# AT32F403Axx register map
Vendor: Keil; Series: AT32F403A; File version: 1.0
CPU: CM4 r0p1, little endian, no MPU, FPU, 4 interrupt priority bits
Registers are 32-bit, read-write, reset 0x0 unless marked. A register's access mark holds for its fields unless they carry their own. Offsets are from the block's base; [hi:lo] are bit positions; {n}, {i} and the like mark numbered series; 'fields as' and 'values as' point back to an identical list.

## XMC — Flexible static memory controller
Base 0xA0000000
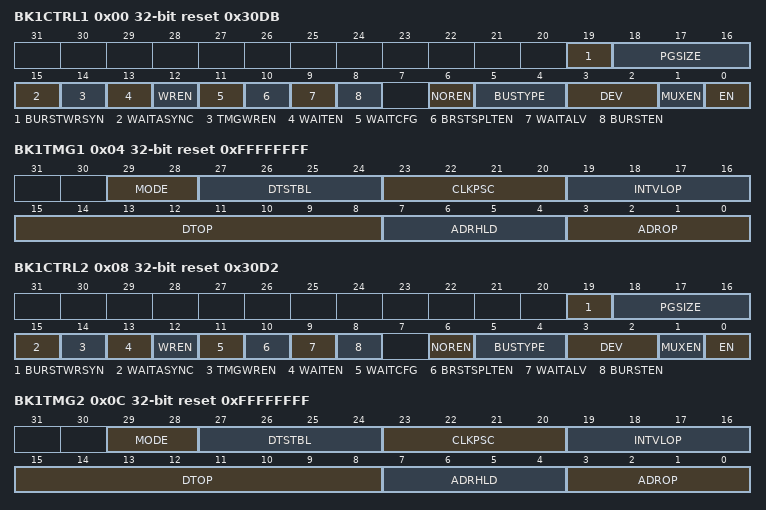
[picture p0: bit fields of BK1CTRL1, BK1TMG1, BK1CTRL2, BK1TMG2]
0x00 BK1CTRL1 reset 0x30DB — SRAM/NOR-Flash chip-select control register 1
  [19] BURSTWRSYN, [18:16] PGSIZE, [15] WAITASYNC, [14] TMGWREN, [13] WAITEN, [12] WREN, [11] WAITCFG, [10] BRSTSPLTEN, [9] WAITALV, [8] BURSTEN, [6] NOREN, [5:4] BUSTYPE, [3:2] DEV, [1] MUXEN, [0] EN
0x04 BK1TMG1 reset 0xFFFFFFFF — SRAM/NOR-Flash chip-select timing register 1
  [29:28] MODE, [27:24] DTSTBL, [23:20] CLKPSC, [19:16] INTVLOP, [15:8] DTOP, [7:4] ADRHLD, [3:0] ADROP
0x08 BK1CTRL2 reset 0x30D2 — SRAM/NOR-Flash chip-select control register 2
  fields as BK1CTRL1
0x0C BK1TMG2 reset 0xFFFFFFFF — SRAM/NOR-Flash chip-select timing register 2
  fields as BK1TMG1
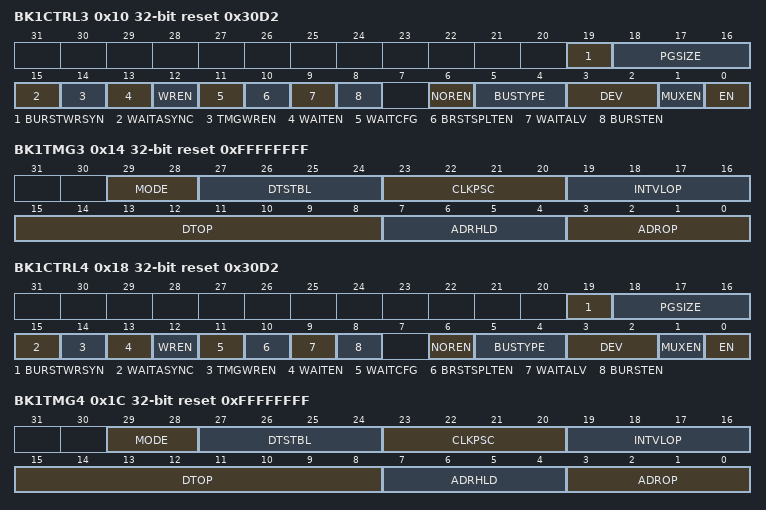
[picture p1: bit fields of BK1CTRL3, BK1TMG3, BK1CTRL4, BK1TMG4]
0x10 BK1CTRL3 reset 0x30D2 — SRAM/NOR-Flash chip-select control register 3
  fields as BK1CTRL1
0x14 BK1TMG3 reset 0xFFFFFFFF — SRAM/NOR-Flash chip-select timing register 3
  fields as BK1TMG1
0x18 BK1CTRL4 reset 0x30D2 — SRAM/NOR-Flash chip-select control register 4
  fields as BK1CTRL1
0x1C BK1TMG4 reset 0xFFFFFFFF — SRAM/NOR-Flash chip-select timing register 4
  fields as BK1TMG1
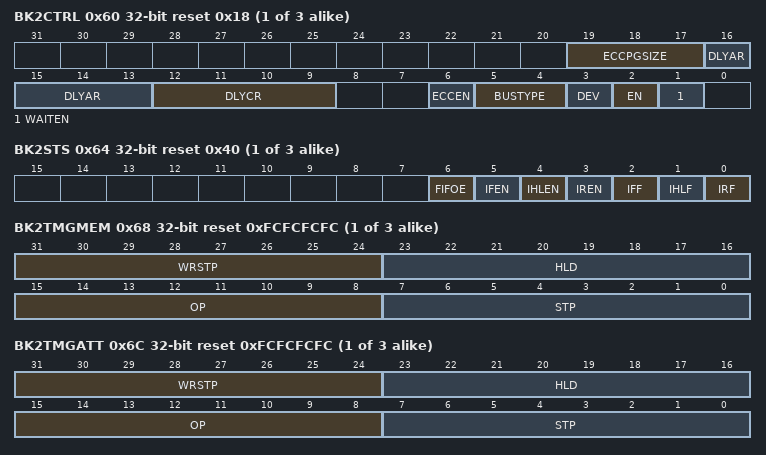
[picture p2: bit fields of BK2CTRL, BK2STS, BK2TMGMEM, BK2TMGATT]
{0x20+0x20*i} BK{i}CTRL reset 0x18 (i=2..4) — PC Card/NAND Flash control register {i}
  [19:17] ECCPGSIZE, [16:13] DLYAR, [12:9] DLYCR, [6] ECCEN, [5:4] BUSTYPE, [3] DEV, [2] EN, [1] WAITEN
{0x24+0x20*i} BK{i}STS reset 0x40 (i=2..4) — FIFO status and interrupt register {i}
  [6] FIFOE ro, [5] IFEN, [4] IHLEN, [3] IREN, [2] IFF, [1] IHLF, [0] IRF
{0x28+0x20*i} BK{i}TMGMEM reset 0xFCFCFCFC (i=2..4) — Common memory space timing register {i}
  [31:24] WRSTP, [23:16] HLD, [15:8] OP, [7:0] STP
{0x2C+0x20*i} BK{i}TMGATT reset 0xFCFCFCFC (i=2..4) — Attribute memory space timing register {i}
  [31:24] WRSTP — Attribute memory x databus HiZ time
  [23:16] HLD — Attribute memory x hold time
  [15:8] OP — Attribute memory x wait time
  [7:0] STP — Attribute memory x setup time
0x74 BK2ECC — ECC result register 2
  [31:0] ECC — ECC result
0x94 BK3ECC — ECC result register 3
  [31:0] ECC — ECC result
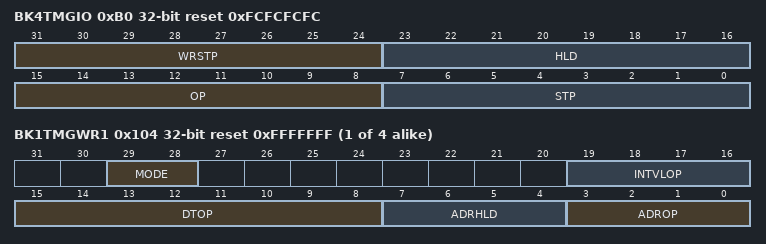
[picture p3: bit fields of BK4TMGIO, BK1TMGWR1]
0xB0 BK4TMGIO reset 0xFCFCFCFC — I/O space timing register 4
  [31:24] WRSTP, [23:16] HLD, [15:8] OP, [7:0] STP
{0xFC+8i} BK1TMGWR{i} reset 0xFFFFFFF (i=1..4) — SRAM/NOR-Flash write timing registers {i}
  [29:28] MODE, [19:16] INTVLOP, [15:8] DTOP, [7:4] ADRHLD, [3:0] ADROP

## PWR — Power control
Base 0x40007000
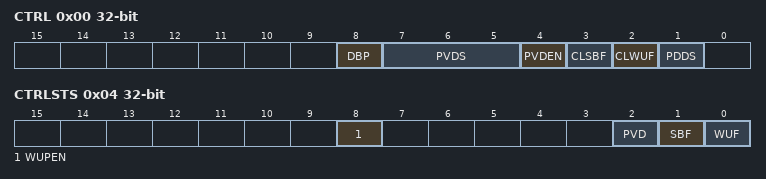
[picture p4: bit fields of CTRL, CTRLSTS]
0x00 CTRL — Power control register (PWR_CTRL)
  [8] DBP — Disable Backup Domain write protection
  [7:5] PVDS — PVD Level Selection
  [4] PVDEN — Power Voltage Detector Enable
  [3] CLSBF — Clear STANDBY Flag
  [2] CLWUF — Clear Wake-up Flag
  [1] PDDS — Power Down Deep Sleep
0x04 CTRLSTS — Power control register (PWR_CTRLST)
  [8] WUPEN — Enable WKUP pin
  [2] PVD ro — PVD Output
  [1] SBF ro — STANDBY Flag
  [0] WUF ro — Wake-Up Flag

## GPIOA — General purpose I/O
Base 0x40010800
Same registers: GPIOB 0x40010C00, GPIOC 0x40011000, GPIOD 0x40011400, GPIOE 0x40011800
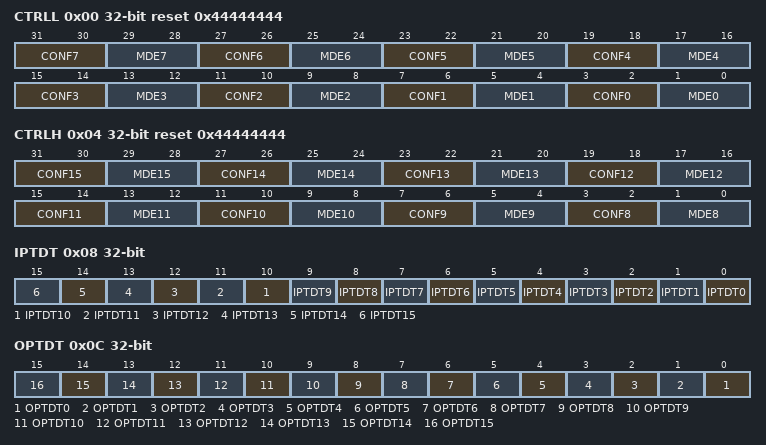
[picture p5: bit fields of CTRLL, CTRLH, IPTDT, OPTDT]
0x00 CTRLL reset 0x44444444 — Port configuration register low (GPIOn_CTRLL)
  [31:30] CONF7 — Port n.7 configuration bits
  [29:28] MDE7 — Port n.7 mode bits
  [27:26] CONF6 — Port n.6 configuration bits
  [25:24] MDE6 — Port n.6 mode bits
  [23:22] CONF5 — Port n.5 configuration bits
  [21:20] MDE5 — Port n.5 mode bits
  [19:18] CONF4 — Port n.4 configuration bits
  [17:16] MDE4 — Port n.4 mode bits
  [15:14] CONF3 — Port n.3 configuration bits
  [13:12] MDE3 — Port n.3 mode bits
  [11:10] CONF2 — Port n.2 configuration bits
  [9:8] MDE2 — Port n.2 mode bits
  [7:6] CONF1 — Port n.1 configuration bits
  [5:4] MDE1 — Port n.1 mode bits
  [3:2] CONF0 — Port n.0 configuration bits
  [1:0] MDE0 — Port n.0 mode bits
0x04 CTRLH reset 0x44444444 — Port configuration register high (GPIOn_CTRLH)
  [31:30] CONF15 — Port n.15 configuration bits
  [29:28] MDE15 — Port n.15 mode bits
  [27:26] CONF14 — Port n.14 configuration bits
  [25:24] MDE14 — Port n.14 mode bits
  [23:22] CONF13 — Port n.13 configuration bits
  [21:20] MDE13 — Port n.13 mode bits
  [19:18] CONF12 — Port n.12 configuration bits
  [17:16] MDE12 — Port n.12 mode bits
  [15:14] CONF11 — Port n.11 configuration bits
  [13:12] MDE11 — Port n.11 mode bits
  [11:10] CONF10 — Port n.10 configuration bits
  [9:8] MDE10 — Port n.10 mode bits
  [7:6] CONF9 — Port n.9 configuration bits
  [5:4] MDE9 — Port n.9 mode bits
  [3:2] CONF8 — Port n.8 configuration bits
  [1:0] MDE8 — Port n.8 mode bits
0x08 IPTDT ro — Port input data register (GPIOn_IPTDT)
  [n] IPTDT{n} (n=0..15) — Port input data
0x0C OPTDT — Port output data register (GPIOn_OPTDT)
  [n] OPTDT{n} (n=0..15) — Port output data
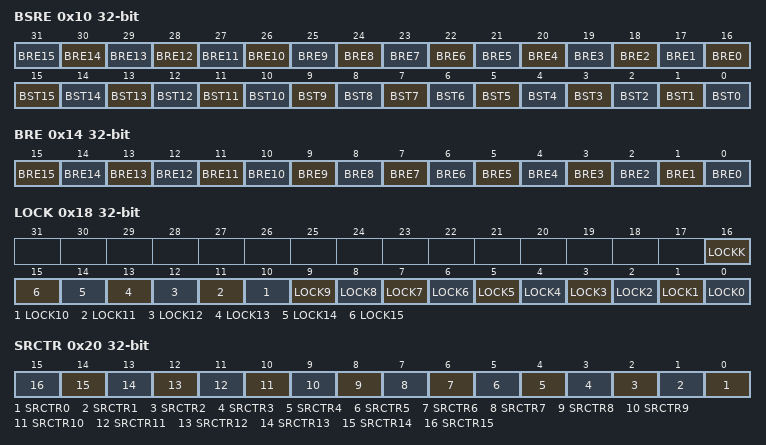
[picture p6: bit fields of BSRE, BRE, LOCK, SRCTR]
0x10 BSRE — Port bit set/reset register (GPIOn_BSRE)
  [n+16] BRE{n} (n=0..15) — Reset bit {n}
  [n] BST{n} (n=3..15) — Set bit {n}
  [2] BST2 — Set bit 1
  [1] BST1 — Set bit 1
  [0] BST0 — Set bit 0
0x14 BRE — Port bit reset register (GPIOn_BRE)
  [n] BRE{n} (n=3..15) — Reset bit {n}
  [2] BRE2 — Reset bit 1
  [1] BRE1 — Reset bit 1
  [0] BRE0 — Reset bit 0
0x18 LOCK — Port configuration lock register
  [16] LOCKK — Lock key
  [n] LOCK{n} (n=0..15) — Port Lock bit {n}
0x20 SRCTR — Port configuration swtich rate control register
  [n] SRCTR{n} (n=0..15) — Port srctr bit {n}
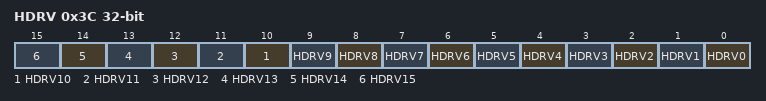
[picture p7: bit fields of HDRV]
0x3C HDRV — Port configuration driver register
  [n] HDRV{n} (n=0..15) — Port hdrv bit {n}

## Notices in the file
Copyright (C) 2012-2014 ARM Limited. All rights reserved.
Purpose: System Viewer Description (SVD) Example (Schema Version 1.1)
This is a description of a none-existent and incomplete device
for demonstration purposes only.
Redistribution and use in source and binary forms, with or without
modification, are permitted provided that the following conditions are met:
- Redistributions of source code must retain the above copyright
notice, this list of conditions and the following disclaimer.
- Redistributions in binary form must reproduce the above copyright
notice, this list of conditions and the following disclaimer in the
documentation and/or other materials provided with the distribution.
- Neither the name of ARM nor the names of its contributors may be used
to endorse or promote products derived from this software without
specific prior written permission.
THIS SOFTWARE IS PROVIDED BY THE COPYRIGHT HOLDERS AND CONTRIBUTORS "AS IS"
AND ANY EXPRESS OR IMPLIED WARRANTIES, INCLUDING, BUT NOT LIMITED TO, THE
IMPLIED WARRANTIES OF MERCHANTABILITY AND FITNESS FOR A PARTICULAR PURPOSE
ARE DISCLAIMED. IN NO EVENT SHALL COPYRIGHT HOLDERS AND CONTRIBUTORS BE
LIABLE FOR ANY DIRECT, INDIRECT, INCIDENTAL, SPECIAL, EXEMPLARY, OR
CONSEQUENTIAL DAMAGES (INCLUDING, BUT NOT LIMITED TO, PROCUREMENT OF
SUBSTITUTE GOODS OR SERVICES; LOSS OF USE, DATA, OR PROFITS; OR BUSINESS
INTERRUPTION) HOWEVER CAUSED AND ON ANY THEORY OF LIABILITY, WHETHER IN
CONTRACT, STRICT LIABILITY, OR TORT (INCLUDING NEGLIGENCE OR OTHERWISE)
ARISING IN ANY WAY OUT OF THE USE OF THIS SOFTWARE, EVEN IF ADVISED OF THE
POSSIBILITY OF SUCH DAMAGE.
